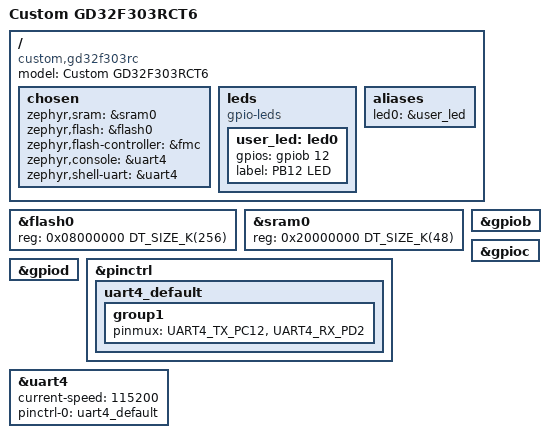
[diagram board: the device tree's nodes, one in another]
/dts-v1/;
#include <gd/gd32f30x/gd32f303.dtsi>
#include <dt-bindings/pinctrl/gd32f303r(b)xx-pinctrl.h>

/ {
	model = "Custom GD32F303RCT6";
	compatible = "custom,gd32f303rc";
	chosen {
		zephyr,sram = &sram0;
		zephyr,flash = &flash0;
		zephyr,flash-controller = &fmc;
		zephyr,console = &uart4;
		zephyr,shell-uart = &uart4;
	};
	leds {
		compatible = "gpio-leds";
		user_led: led0 {
			gpios = <&gpiob 12 GPIO_ACTIVE_HIGH>;
			label = "PB12 LED";
		};
	};
	aliases { led0 = &user_led; };
};

&flash0 { reg = <0x08000000 DT_SIZE_K(256)>; };
&sram0 { reg = <0x20000000 DT_SIZE_K(48)>; };
&gpiob { status = "okay"; };
&gpioc { status = "okay"; };
&gpiod { status = "okay"; };
&pinctrl {
	uart4_default: uart4_default {
		group1 {
			pinmux = <UART4_TX_PC12>, <UART4_RX_PD2>;
		};
	};
};
&uart4 {
	status = "okay";
	current-speed = <115200>;
	pinctrl-0 = <&uart4_default>;
	pinctrl-names = "default";
};
